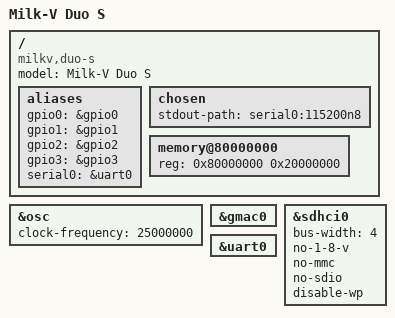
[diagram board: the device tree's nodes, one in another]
// SPDX-License-Identifier: (GPL-2.0 OR MIT)
/*
 * Copyright (C) 2024 Michael Opdenacker <michael.opdenacker@bootlin.com>
 */

/dts-v1/;

#include "cv1812h.dtsi"

/ {
	model = "Milk-V Duo S";
	compatible = "milkv,duo-s", "sophgo,cv1812h";

	aliases {
		gpio0 = &gpio0;
		gpio1 = &gpio1;
		gpio2 = &gpio2;
		gpio3 = &gpio3;
		serial0 = &uart0;
	};

	chosen {
		stdout-path = "serial0:115200n8";
	};

	memory@80000000 {
		reg = <0x80000000 0x20000000>;
	};
};

&osc {
	clock-frequency = <25000000>;
};

&gmac0 {
	status = "okay";
};

&sdhci0 {
	status = "okay";
	bus-width = <4>;
	no-1-8-v;
	no-mmc;
	no-sdio;
	disable-wp;
};

&uart0 {
	status = "okay";
};
